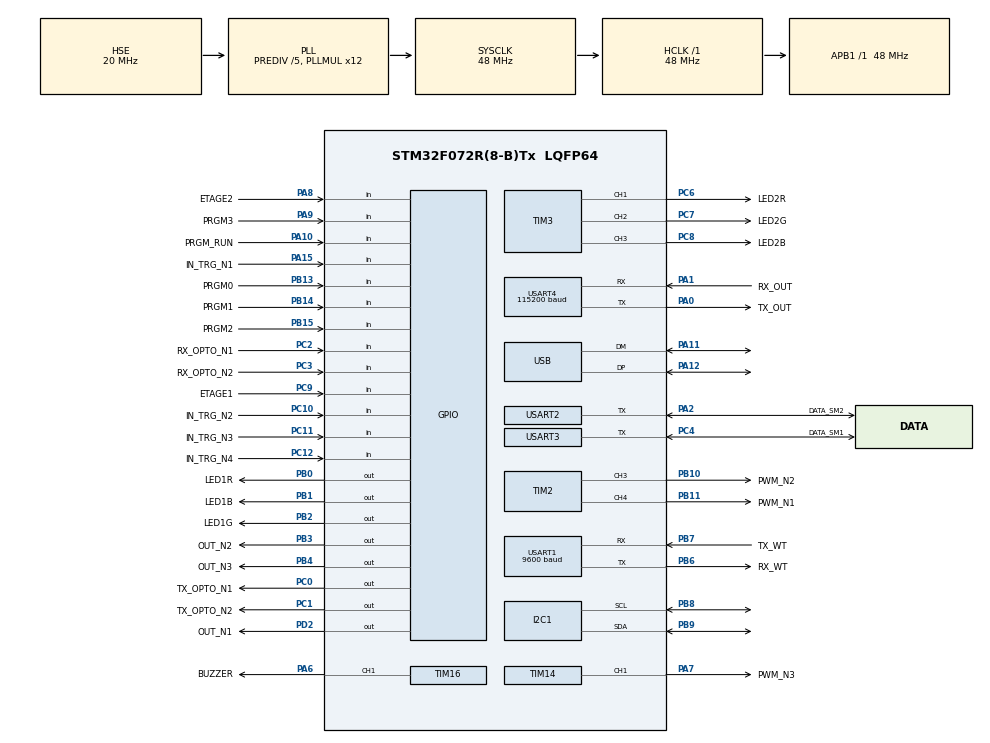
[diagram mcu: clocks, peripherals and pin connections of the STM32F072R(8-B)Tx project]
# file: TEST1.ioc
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I2C1.GeneralCallMode=I2C_GENERALCALL_DISABLE
I2C1.NoStretchMode=I2C_NOSTRETCH_DISABLE
I2C1.Timing=0x10805D88
Mcu.Family=STM32F0
Mcu.Name=STM32F072R(8-B)Tx
Mcu.Package=LQFP64
NVIC.USART1_IRQn=true\:0\:0\:false\:false\:true\:true\:true\:true
NVIC.USART2_IRQn=true\:0\:0\:false\:false\:true\:true\:true\:true
NVIC.USART3_4_IRQn=true\:0\:0\:false\:false\:true\:true\:true\:true
NVIC.USB_IRQn=true\:0\:0\:false\:false\:true\:false\:true\:true
PA0.GPIO_Label=TX_OUT
PA0.Mode=Asynchronous
PA0.Signal=USART4_TX
PA1.GPIO_Label=RX_OUT
PA1.Mode=Asynchronous
PA1.Signal=USART4_RX
PA10.GPIO_Label=PRGM_RUN
PA10.GPIO_PuPd=GPIO_PULLDOWN
PA10.Signal=GPIO_Input
PA11.Mode=Device
PA11.Signal=USB_DM
PA12.Mode=Device
PA12.Signal=USB_DP
PA13.Mode=Serial_Wire
PA13.Signal=SYS_SWDIO
PA14.Mode=Serial_Wire
PA14.Signal=SYS_SWCLK
PA15.GPIO_Label=IN_TRG_N1
PA15.Signal=GPIO_Input
PA2.GPIO_Label=DATA_SM2
PA2.Mode=Half_duplex(single_wire_mode)
PA2.Signal=USART2_TX
PA6.GPIO_Label=BUZZER
PA6.Signal=S_TIM16_CH1
PA7.GPIO_Label=PWM_N3
PA7.Signal=S_TIM14_CH1
PA8.GPIO_Label=ETAGE2
PA8.GPIO_PuPd=GPIO_PULLUP
PA8.Signal=GPIO_Input
PA9.GPIO_Label=PRGM3
PA9.GPIO_PuPd=GPIO_PULLDOWN
PA9.Signal=GPIO_Input
PB0.GPIO_Label=LED1R
PB0.PinState=GPIO_PIN_SET
PB0.Signal=GPIO_Output
PB1.GPIO_Label=LED1B
PB1.PinState=GPIO_PIN_SET
PB1.Signal=GPIO_Output
PB10.GPIO_Label=PWM_N2
PB10.Signal=S_TIM2_CH3
PB11.GPIO_Label=PWM_N1
PB11.Signal=S_TIM2_CH4
PB13.GPIO_Label=PRGM0
PB13.GPIO_PuPd=GPIO_PULLDOWN
PB13.Signal=GPIO_Input
PB14.GPIO_Label=PRGM1
PB14.GPIO_PuPd=GPIO_PULLDOWN
PB14.Signal=GPIO_Input
PB15.GPIO_Label=PRGM2
PB15.GPIO_PuPd=GPIO_PULLDOWN
PB15.Signal=GPIO_Input
PB2.GPIO_Label=LED1G
PB2.PinState=GPIO_PIN_SET
PB2.Signal=GPIO_Output
PB3.GPIO_Label=OUT_N2
PB3.Signal=GPIO_Output
PB4.GPIO_Label=OUT_N3
PB4.Signal=GPIO_Output
PB6.GPIO_Label=RX_WT
PB6.Mode=Asynchronous
PB6.Signal=USART1_TX
PB7.GPIO_Label=TX_WT
PB7.Mode=Asynchronous
PB7.Signal=USART1_RX
PB8.Mode=I2C
PB8.Signal=I2C1_SCL
PB9.Mode=I2C
PB9.Signal=I2C1_SDA
PC0.GPIO_Label=TX_OPTO_N1
PC0.Signal=GPIO_Output
PC1.GPIO_Label=TX_OPTO_N2
PC1.Signal=GPIO_Output
PC10.GPIO_Label=IN_TRG_N2
PC10.Signal=GPIO_Input
PC11.GPIO_Label=IN_TRG_N3
PC11.Signal=GPIO_Input
PC12.GPIO_Label=IN_TRG_N4
PC12.Signal=GPIO_Input
PC14-OSC32_IN.Mode=LSE-External-Oscillator
PC14-OSC32_IN.Signal=RCC_OSC32_IN
PC15-OSC32_OUT.Mode=LSE-External-Oscillator
PC15-OSC32_OUT.Signal=RCC_OSC32_OUT
PC2.GPIO_Label=RX_OPTO_N1
PC2.Signal=GPIO_Input
PC3.GPIO_Label=RX_OPTO_N2
PC3.Signal=GPIO_Input
PC4.GPIO_Label=DATA_SM1
PC4.Mode=Half_duplex(single_wire_mode)
PC4.Signal=USART3_TX
PC6.GPIO_Label=LED2R
PC6.Signal=S_TIM3_CH1
PC7.GPIO_Label=LED2G
PC7.Signal=S_TIM3_CH2
PC8.GPIO_Label=LED2B
PC8.Signal=S_TIM3_CH3
PC9.GPIO_Label=ETAGE1
PC9.GPIO_PuPd=GPIO_PULLUP
PC9.Signal=GPIO_Input
PD2.GPIO_Label=OUT_N1
PD2.Signal=GPIO_Output
PF0-OSC_IN.Mode=HSE-External-Oscillator
PF0-OSC_IN.Signal=RCC_OSC_IN
PF1-OSC_OUT.Mode=HSE-External-Oscillator
PF1-OSC_OUT.Signal=RCC_OSC_OUT
ProjectManager.HeapSize=0x200
ProjectManager.StackSize=0x400
ProjectManager.TargetToolchain=CMake
RCC.AHBFreq_Value=48000000
RCC.APB1Freq_Value=48000000
RCC.APB1TimFreq_Value=48000000
RCC.HCLKFreq_Value=48000000
RCC.HSE_VALUE=20000000
RCC.I2c1ClockSelection=RCC_I2C1CLKSOURCE_SYSCLK
RCC.PLLDivider=RCC_PREDIV_DIV5
RCC.PLLMUL=RCC_PLL_MUL12
RCC.SYSCLKFreq_VALUE=48000000
RCC.SYSCLKSource=RCC_SYSCLKSOURCE_PLLCLK
RCC.USBClockSelection=RCC_USBCLKSOURCE_PLL
RCC.USBFreq_Value=48000000
SH.S_TIM14_CH1.0=TIM14_CH1,PWM Generation1 CH1
SH.S_TIM16_CH1.0=TIM16_CH1,PWM Generation1 CH1
SH.S_TIM2_CH3.0=TIM2_CH3,PWM Generation3 CH3
SH.S_TIM2_CH4.0=TIM2_CH4,PWM Generation4 CH4
SH.S_TIM3_CH1.0=TIM3_CH1,PWM Generation1 CH1
SH.S_TIM3_CH2.0=TIM3_CH2,PWM Generation2 CH2
SH.S_TIM3_CH3.0=TIM3_CH3,PWM Generation3 CH3
TIM14.Channel=TIM_CHANNEL_1
TIM16.Channel=TIM_CHANNEL_1
TIM2.Channel-PWM\ Generation3\ CH3=TIM_CHANNEL_3
TIM2.Channel-PWM\ Generation4\ CH4=TIM_CHANNEL_4
TIM3.Channel-PWM\ Generation1\ CH1=TIM_CHANNEL_1
TIM3.Channel-PWM\ Generation2\ CH2=TIM_CHANNEL_2
TIM3.Channel-PWM\ Generation3\ CH3=TIM_CHANNEL_3
USART1.BaudRate=9600
USART1.VirtualMode-Asynchronous=VM_ASYNC
USART2.BaudRate=115200
USART2.VirtualMode-Half_duplex(single_wire_mode)=VM_ASYNC
USART3.BaudRate=115200
USART3.VirtualMode-Half_duplex(single_wire_mode)=VM_ASYNC
USART4.BaudRate=115200
USART4.SwapParam=ADVFEATURE_SWAP_ENABLE
USART4.VirtualMode-Asynchronous=VM_ASYNC
USB_DEVICE.CLASS_NAME_FS=CDC
USB_DEVICE.VirtualMode=Cdc
USB_DEVICE.VirtualModeFS=Cdc_FS
VP_TIM14_VS_ClockSourceINT.Mode=Enable_Timer
VP_TIM16_VS_ClockSourceINT.Mode=Enable_Timer
VP_TIM2_VS_ClockSourceINT.Mode=Internal
VP_TIM3_VS_ClockSourceINT.Mode=Internal
VP_USB_DEVICE_VS_USB_DEVICE_CDC_FS.Mode=CDC_FS
board=custom

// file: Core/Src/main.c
/* USER CODE BEGIN Header */
/**
  ******************************************************************************
  * @file           : main.c
  * @brief          : Main program body
  ******************************************************************************
  * @attention
  *
  * Copyright (c) 2026 STMicroelectronics.
  * All rights reserved.
  *
  * This software is licensed under terms that can be found in the LICENSE file
  * in the root directory of this software component.
  * If no LICENSE file comes with this software, it is provided AS-IS.
  *
  ******************************************************************************
  */
/* USER CODE END Header */
#include "main.h"
#include "i2c.h"
#include "tim.h"
#include "usart.h"
#include "usb_device.h"
#include "gpio.h"

/* USER CODE BEGIN Includes */

#include "project.h"

/* USER CODE END Includes */

void SystemClock_Config(void);

int main(void)
{

  /* MCU Configuration--------------------------------------------------------*/

  /* Reset of all peripherals, Initializes the Flash interface and the Systick. */
  HAL_Init();

  /* Configure the system clock */
  SystemClock_Config();

  /* Initialize all configured peripherals */
  MX_GPIO_Init();
  MX_TIM2_Init();
  MX_TIM3_Init();
  MX_TIM14_Init();
  MX_TIM16_Init();
  MX_USART1_UART_Init();
  MX_USART2_UART_Init();
  MX_USART3_UART_Init();
  MX_USART4_UART_Init();
  MX_I2C1_Init();
  MX_USB_DEVICE_Init();
  /* USER CODE BEGIN 2 */

	setup();

  /* USER CODE END 2 */

  /* Infinite loop */
  /* USER CODE BEGIN WHILE */
	while (1)
	{

    loop();

    /* USER CODE END WHILE */

	}
}

void SystemClock_Config(void)
{
  RCC_OscInitTypeDef RCC_OscInitStruct = {0};
  RCC_ClkInitTypeDef RCC_ClkInitStruct = {0};
  RCC_PeriphCLKInitTypeDef PeriphClkInit = {0};

  /** Initializes the RCC Oscillators according to the specified parameters
  * in the RCC_OscInitTypeDef structure.
  */
  RCC_OscInitStruct.OscillatorType = RCC_OSCILLATORTYPE_HSE;
  RCC_OscInitStruct.HSEState = RCC_HSE_ON;
  RCC_OscInitStruct.PLL.PLLState = RCC_PLL_ON;
  RCC_OscInitStruct.PLL.PLLSource = RCC_PLLSOURCE_HSE;
  RCC_OscInitStruct.PLL.PLLMUL = RCC_PLL_MUL12;
  RCC_OscInitStruct.PLL.PREDIV = RCC_PREDIV_DIV5;
  if (HAL_RCC_OscConfig(&RCC_OscInitStruct) != HAL_OK)
  {
    Error_Handler();
  }

  /** Initializes the CPU, AHB and APB buses clocks
  */
  RCC_ClkInitStruct.ClockType = RCC_CLOCKTYPE_HCLK|RCC_CLOCKTYPE_SYSCLK
                              |RCC_CLOCKTYPE_PCLK1;
  RCC_ClkInitStruct.SYSCLKSource = RCC_SYSCLKSOURCE_PLLCLK;
  RCC_ClkInitStruct.AHBCLKDivider = RCC_SYSCLK_DIV1;
  RCC_ClkInitStruct.APB1CLKDivider = RCC_HCLK_DIV1;

  if (HAL_RCC_ClockConfig(&RCC_ClkInitStruct, FLASH_LATENCY_1) != HAL_OK)
  {
    Error_Handler();
  }
  PeriphClkInit.PeriphClockSelection = RCC_PERIPHCLK_USB|RCC_PERIPHCLK_USART1
                              |RCC_PERIPHCLK_USART2|RCC_PERIPHCLK_I2C1;
  PeriphClkInit.Usart1ClockSelection = RCC_USART1CLKSOURCE_PCLK1;
  PeriphClkInit.Usart2ClockSelection = RCC_USART2CLKSOURCE_PCLK1;
  PeriphClkInit.I2c1ClockSelection = RCC_I2C1CLKSOURCE_SYSCLK;
  PeriphClkInit.UsbClockSelection = RCC_USBCLKSOURCE_PLL;

  if (HAL_RCCEx_PeriphCLKConfig(&PeriphClkInit) != HAL_OK)
  {
    Error_Handler();
  }
}

void Error_Handler(void)
{
  /* USER CODE BEGIN Error_Handler_Debug */
  /* User can add his own implementation to report the HAL error return state */
  __disable_irq();
  while (1)
  {
    HAL_GPIO_WritePin(LED1R_GPIO_Port, LED1R_Pin, GPIO_PIN_RESET);
  }
  /* USER CODE END Error_Handler_Debug */
}
